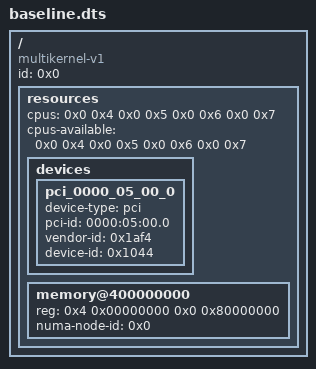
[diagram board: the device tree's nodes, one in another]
/dts-v1/;

/ {
    compatible = "multikernel-v1";
    id = <0x0>;
    resources {
        #address-cells = <0x2>;
        #size-cells = <0x2>;
        cpus = <0x0 0x4 0x0 0x5 0x0 0x6 0x0 0x7>;
        cpus-available = <0x0 0x4 0x0 0x5 0x0 0x6 0x0 0x7>;
        devices {
            pci_0000_05_00_0 {
                device-type = "pci";
                pci-id = "0000:05:00.0";
                vendor-id = <0x1af4>;
                device-id = <0x1044>;
            };
        };
        memory@400000000 {
            device_type = "memory";
            reg = <0x4 0x00000000 0x0 0x80000000>;
            numa-node-id = <0x0>;
        };
    };
};
